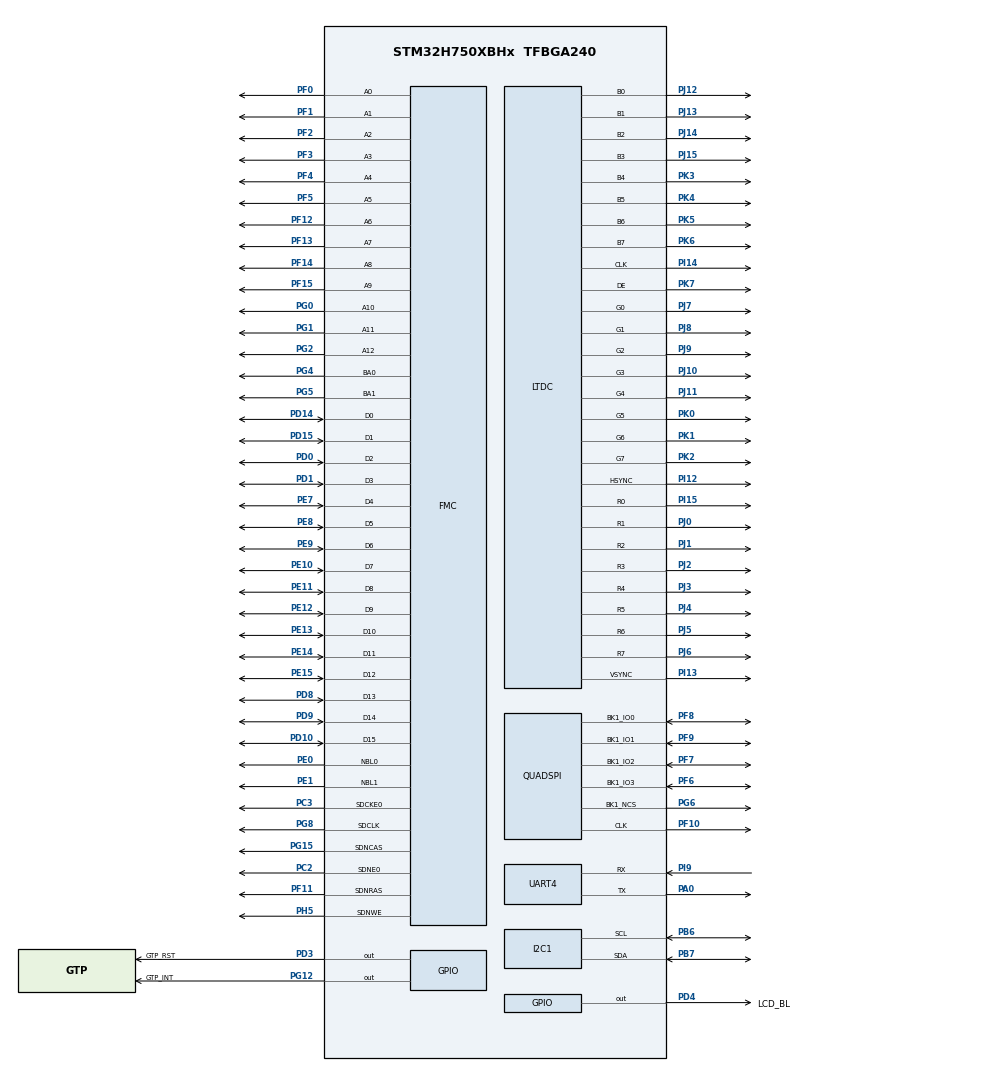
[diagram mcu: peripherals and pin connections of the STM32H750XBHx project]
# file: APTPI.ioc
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CORTEX_M7.BaseAddress-Cortex_Memory_Protection_Unit_Region0_Settings=0xC0000000
CORTEX_M7.CPU_DCache=Enabled
CORTEX_M7.CPU_ICache=Enabled
CORTEX_M7.Enable-Cortex_Memory_Protection_Unit_Region0_Settings=MPU_REGION_ENABLE
CORTEX_M7.IsCacheable-Cortex_Memory_Protection_Unit_Region0_Settings=MPU_ACCESS_CACHEABLE
CORTEX_M7.IsShareable-Cortex_Memory_Protection_Unit_Region0_Settings=MPU_ACCESS_SHAREABLE
CORTEX_M7.MPU_Control=__NULL
CORTEX_M7.Size-Cortex_Memory_Protection_Unit_Region0_Settings=MPU_REGION_SIZE_16MB
DMA2D.ColorMode=DMA2D_OUTPUT_ARGB8888
FMC.BankMapConfig=FMC_SWAPBMAP_DISABLE
FMC.CASLatency1=FMC_SDRAM_CAS_LATENCY_3
FMC.ColumnBitsNumber1=FMC_SDRAM_COLUMN_BITS_NUM_9
FMC.ExitSelfRefreshDelay1=8
FMC.LoadToActiveDelay1=2
FMC.RCDDelay1=2
FMC.RPDelay1=2
FMC.ReadBurst1=FMC_SDRAM_RBURST_ENABLE
FMC.ReadBurst2=FMC_SDRAM_RBURST_ENABLE
FMC.ReadPipeDelay1=FMC_SDRAM_RPIPE_DELAY_1
FMC.ReadPipeDelay2=FMC_SDRAM_RPIPE_DELAY_1
FMC.RowCycleDelay1=7
FMC.RowCycleDelay2=7
FMC.SDClockPeriod1=FMC_SDRAM_CLOCK_PERIOD_2
FMC.SDClockPeriod2=FMC_SDRAM_CLOCK_PERIOD_2
FMC.SelfRefreshTime1=6
FMC.WriteProtection1=FMC_SDRAM_WRITE_PROTECTION_DISABLE
FMC.WriteRecoveryTime1=5
FREERTOS.Tasks01=defaultTask,24,4096,StartDefaultTask,Default,NULL,Dynamic,NULL,NULL
FREERTOS.configTOTAL_HEAP_SIZE=40960
FREERTOS.configUSE_NEWLIB_REENTRANT=1
I2C1.CustomTiming=Enabled
I2C1.I2C_Fall_Time=0
I2C1.I2C_Rise_Time=0
I2C1.Speed=50
I2C1.Timing=0x90913232
LTDC.ActiveW=800
LTDC.Alpha0_L0=0
LTDC.Alpha_L0=0xFF
LTDC.BlendingFactor1_L0=LTDC_BLENDING_FACTOR1_CA
LTDC.BlendingFactor2_L0=LTDC_BLENDING_FACTOR2_CA
LTDC.FBStartAdress_L0=0xC0000000
LTDC.HBP=88
LTDC.HFP=40
LTDC.HSync=1
LTDC.ImageHeight_L0=480
LTDC.ImageWidth_L0=800
LTDC.Layers=0
LTDC.PixelFormat_L0=LTDC_PIXEL_FORMAT_ARGB8888
LTDC.VBP=32
LTDC.VFP=13
LTDC.VSync=1
LTDC.WindowX1_L0=800
LTDC.WindowY1_L0=480
Mcu.Family=STM32H7
Mcu.Name=STM32H750XBHx
Mcu.Package=TFBGA240
NVIC.DMA2D_IRQn=true\:5\:0\:true\:false\:true\:true\:true\:true
NVIC.LTDC_IRQn=true\:5\:0\:true\:false\:true\:true\:true\:true
NVIC.PriorityGroup=NVIC_PRIORITYGROUP_4
NVIC.TIM1_UP_IRQn=true\:15\:0\:false\:false\:true\:false\:false\:true
NVIC.TimeBase=TIM1_UP_IRQn
NVIC.TimeBaseIP=TIM1
PA0.Mode=Asynchronous
PA0.Signal=UART4_TX
PA13\ (JTMS/SWDIO).Mode=Serial_Wire
PA13\ (JTMS/SWDIO).Signal=DEBUG_JTMS-SWDIO
PA14\ (JTCK/SWCLK).Mode=Serial_Wire
PA14\ (JTCK/SWCLK).Signal=DEBUG_JTCK-SWCLK
PA4.GPIO_Speed=GPIO_SPEED_FREQ_VERY_HIGH
PA4.Signal=SPI1_NSS
PA5.GPIO_Speed=GPIO_SPEED_FREQ_VERY_HIGH
PA5.Signal=SPI1_SCK
PB5.GPIO_Speed=GPIO_SPEED_FREQ_VERY_HIGH
PB5.Signal=SPI1_MOSI
PB6.GPIO_Speed=GPIO_SPEED_FREQ_VERY_HIGH
PB6.Mode=I2C
PB6.Signal=I2C1_SCL
PB7.GPIO_Speed=GPIO_SPEED_FREQ_VERY_HIGH
PB7.Mode=I2C
PB7.Signal=I2C1_SDA
PC14-OSC32_IN\ (OSC32_IN).Mode=LSE-External-Oscillator
PC14-OSC32_IN\ (OSC32_IN).Signal=RCC_OSC32_IN
PC15-OSC32_OUT\ (OSC32_OUT).Mode=LSE-External-Oscillator
PC15-OSC32_OUT\ (OSC32_OUT).Signal=RCC_OSC32_OUT
PC2.Mode=SdramChipSelect1_1
PC2.Signal=FMC_SDNE0
PC3.Mode=SdramChipSelect1_1
PC3.Signal=FMC_SDCKE0
PD0.Signal=FMC_D2_DA2
PD1.Signal=FMC_D3_DA3
PD10.Signal=FMC_D15_DA15
PD14.Signal=FMC_D0_DA0
PD15.Signal=FMC_D1_DA1
PD3.GPIO_Label=GTP_RST
PD3.GPIO_PuPd=GPIO_PULLDOWN
PD3.Signal=GPIO_Output
PD4.GPIO_Label=LCD_BL
PD4.PinState=GPIO_PIN_SET
PD4.Signal=GPIO_Output
PD8.Signal=FMC_D13_DA13
PD9.Signal=FMC_D14_DA14
PE0.Signal=FMC_NBL0
PE1.Signal=FMC_NBL1
PE10.Signal=FMC_D7_DA7
PE11.Signal=FMC_D8_DA8
PE12.Signal=FMC_D9_DA9
PE13.Signal=FMC_D10_DA10
PE14.Signal=FMC_D11_DA11
PE15.Signal=FMC_D12_DA12
PE7.Signal=FMC_D4_DA4
PE8.Signal=FMC_D5_DA5
PE9.Signal=FMC_D6_DA6
PF0.Signal=FMC_A0
PF1.Signal=FMC_A1
PF10.GPIO_Speed=GPIO_SPEED_FREQ_VERY_HIGH
PF10.Mode=Single Bank 1
PF10.Signal=QUADSPI_CLK
PF11.Signal=FMC_SDNRAS
PF12.Signal=FMC_A6
PF13.Signal=FMC_A7
PF14.Signal=FMC_A8
PF15.Signal=FMC_A9
PF2.Signal=FMC_A2
PF3.Signal=FMC_A3
PF4.Signal=FMC_A4
PF5.Signal=FMC_A5
PF6.GPIO_Speed=GPIO_SPEED_FREQ_VERY_HIGH
PF6.Mode=Single Bank 1
PF6.Signal=QUADSPI_BK1_IO3
PF7.GPIO_Speed=GPIO_SPEED_FREQ_VERY_HIGH
PF7.Mode=Single Bank 1
PF7.Signal=QUADSPI_BK1_IO2
PF8.GPIO_Speed=GPIO_SPEED_FREQ_VERY_HIGH
PF8.Mode=Single Bank 1
PF8.Signal=QUADSPI_BK1_IO0
PF9.GPIO_Speed=GPIO_SPEED_FREQ_VERY_HIGH
PF9.Mode=Single Bank 1
PF9.Signal=QUADSPI_BK1_IO1
PG0.Signal=FMC_A10
PG1.Signal=FMC_A11
PG12.GPIO_Label=GTP_INT
PG12.GPIO_PuPd=GPIO_PULLDOWN
PG12.Signal=GPIO_Output
PG15.Signal=FMC_SDNCAS
PG2.Signal=FMC_A12
PG4.Signal=FMC_A14_BA0
PG5.Signal=FMC_A15_BA1
PG6.GPIO_Speed=GPIO_SPEED_FREQ_VERY_HIGH
PG6.Mode=Single Bank 1
PG6.Signal=QUADSPI_BK1_NCS
PG8.Signal=FMC_SDCLK
PG9.GPIO_Speed=GPIO_SPEED_FREQ_VERY_HIGH
PG9.Signal=SPI1_MISO
PH0-OSC_IN\ (PH0).Mode=HSE-External-Oscillator
PH0-OSC_IN\ (PH0).Signal=RCC_OSC_IN
PH1-OSC_OUT\ (PH1).Mode=HSE-External-Oscillator
PH1-OSC_OUT\ (PH1).Signal=RCC_OSC_OUT
PH5.Signal=FMC_SDNWE
PI12.Mode=RGB888
PI12.Signal=LTDC_HSYNC
PI13.Mode=RGB888
PI13.Signal=LTDC_VSYNC
PI14.Mode=RGB888
PI14.Signal=LTDC_CLK
PI15.Mode=RGB888
PI15.Signal=LTDC_R0
PI9.Mode=Asynchronous
PI9.Signal=UART4_RX
PJ0.Mode=RGB888
PJ0.Signal=LTDC_R1
PJ1.Mode=RGB888
PJ1.Signal=LTDC_R2
PJ10.Mode=RGB888
PJ10.Signal=LTDC_G3
PJ11.Mode=RGB888
PJ11.Signal=LTDC_G4
PJ12.Mode=RGB888
PJ12.Signal=LTDC_B0
PJ13.Mode=RGB888
PJ13.Signal=LTDC_B1
PJ14.Mode=RGB888
PJ14.Signal=LTDC_B2
PJ15.Mode=RGB888
PJ15.Signal=LTDC_B3
PJ2.Mode=RGB888
PJ2.Signal=LTDC_R3
PJ3.Mode=RGB888
PJ3.Signal=LTDC_R4
PJ4.Mode=RGB888
PJ4.Signal=LTDC_R5
PJ5.Mode=RGB888
PJ5.Signal=LTDC_R6
PJ6.Mode=RGB888
PJ6.Signal=LTDC_R7
PJ7.Mode=RGB888
PJ7.Signal=LTDC_G0
PJ8.Mode=RGB888
PJ8.Signal=LTDC_G1
PJ9.Mode=RGB888
PJ9.Signal=LTDC_G2
PK0.Mode=RGB888
PK0.Signal=LTDC_G5
PK1.Mode=RGB888
PK1.Signal=LTDC_G6
PK2.Mode=RGB888
PK2.Signal=LTDC_G7
PK3.Mode=RGB888
PK3.Signal=LTDC_B4
PK4.Mode=RGB888
PK4.Signal=LTDC_B5
PK5.Mode=RGB888
PK5.Signal=LTDC_B6
PK6.Mode=RGB888
PK6.Signal=LTDC_B7
PK7.Mode=RGB888
PK7.Signal=LTDC_DE
ProjectManager.HeapSize=0x200
ProjectManager.StackSize=0x400
ProjectManager.TargetToolchain=STM32CubeIDE
QUADSPI.ChipSelectHighTime=QSPI_CS_HIGH_TIME_6_CYCLE
QUADSPI.ClockMode=QSPI_CLOCK_MODE_0
QUADSPI.ClockPrescaler=1
QUADSPI.FifoThreshold=4
QUADSPI.FlashSize=22
QUADSPI.SampleShifting=QSPI_SAMPLE_SHIFTING_HALFCYCLE
RCC.ADCFreq_Value=250000000
RCC.APB1Freq_Value=100000000
RCC.APB2Freq_Value=100000000
RCC.APB3Freq_Value=100000000
RCC.APB4Freq_Value=100000000
RCC.CortexFreq_Value=400000000
RCC.D1PPRE=RCC_APB3_DIV2
RCC.D2PPRE1=RCC_APB1_DIV2
RCC.D2PPRE2=RCC_APB2_DIV2
RCC.D3PPRE=RCC_APB4_DIV2
RCC.DIVM1=5
RCC.DIVM2=5
RCC.DIVM3=5
RCC.DIVN1=160
RCC.DIVN2=100
RCC.DIVN3=192
RCC.DIVQ1=8
RCC.DIVR3=32
RCC.FMCCLockSelection=RCC_FMCCLKSOURCE_PLL2
RCC.HCLKFreq_Value=200000000
RCC.HPRE=RCC_HCLK_DIV2
RCC.PLLFRACN=0
RCC.PLLSourceVirtual=RCC_PLLSOURCE_HSE
RCC.PWR_Regulator_Voltage_Scale=PWR_REGULATOR_VOLTAGE_SCALE1
RCC.SYSCLKFreq_VALUE=400000000
RCC.SYSCLKSource=RCC_SYSCLKSOURCE_PLLCLK
RCC.USBFreq_Value=100000000
SH.FMC_A0.0=FMC_A0,13b-sda1
SH.FMC_A1.0=FMC_A1,13b-sda1
SH.FMC_A10.0=FMC_A10,13b-sda1
SH.FMC_A11.0=FMC_A11,13b-sda1
SH.FMC_A12.0=FMC_A12,13b-sda1
SH.FMC_A14_BA0.0=FMC_BA0,FourSdramBanks1
SH.FMC_A15_BA1.0=FMC_BA1,FourSdramBanks1
SH.FMC_A2.0=FMC_A2,13b-sda1
SH.FMC_A3.0=FMC_A3,13b-sda1
SH.FMC_A4.0=FMC_A4,13b-sda1
SH.FMC_A5.0=FMC_A5,13b-sda1
SH.FMC_A6.0=FMC_A6,13b-sda1
SH.FMC_A7.0=FMC_A7,13b-sda1
SH.FMC_A8.0=FMC_A8,13b-sda1
SH.FMC_A9.0=FMC_A9,13b-sda1
SH.FMC_D0_DA0.0=FMC_D0,sd-16b-d1
SH.FMC_D10_DA10.0=FMC_D10,sd-16b-d1
SH.FMC_D11_DA11.0=FMC_D11,sd-16b-d1
SH.FMC_D12_DA12.0=FMC_D12,sd-16b-d1
SH.FMC_D13_DA13.0=FMC_D13,sd-16b-d1
SH.FMC_D14_DA14.0=FMC_D14,sd-16b-d1
SH.FMC_D15_DA15.0=FMC_D15,sd-16b-d1
SH.FMC_D1_DA1.0=FMC_D1,sd-16b-d1
SH.FMC_D2_DA2.0=FMC_D2,sd-16b-d1
SH.FMC_D3_DA3.0=FMC_D3,sd-16b-d1
SH.FMC_D4_DA4.0=FMC_D4,sd-16b-d1
SH.FMC_D5_DA5.0=FMC_D5,sd-16b-d1
SH.FMC_D6_DA6.0=FMC_D6,sd-16b-d1
SH.FMC_D7_DA7.0=FMC_D7,sd-16b-d1
SH.FMC_D8_DA8.0=FMC_D8,sd-16b-d1
SH.FMC_D9_DA9.0=FMC_D9,sd-16b-d1
SH.FMC_NBL0.0=FMC_NBL0,Sd2ByteEnable1
SH.FMC_NBL1.0=FMC_NBL1,Sd2ByteEnable1
SH.FMC_SDCLK.0=FMC_SDCLK,13b-sda1
SH.FMC_SDNCAS.0=FMC_SDNCAS,13b-sda1
SH.FMC_SDNRAS.0=FMC_SDNRAS,13b-sda1
SH.FMC_SDNWE.0=FMC_SDNWE,13b-sda1
STMicroelectronics.X-CUBE-TOUCHGFX.4.18.1.ApplicationCcGraphicsJjApplication=TouchGFXOoGenerator
STMicroelectronics.X-CUBE-TOUCHGFX.4.18.1.tgfx_address1=0xC0000000
STMicroelectronics.X-CUBE-TOUCHGFX.4.18.1.tgfx_address2=0xC1000000
STMicroelectronics.X-CUBE-TOUCHGFX.4.18.1.tgfx_buffering_strategy=Double
STMicroelectronics.X-CUBE-TOUCHGFX.4.18.1.tgfx_display_interface=disp_ltdc
STMicroelectronics.X-CUBE-TOUCHGFX.4.18.1.tgfx_hardware_accelerator=dma_2d
STMicroelectronics.X-CUBE-TOUCHGFX.4.18.1.tgfx_location=By Address
STMicroelectronics.X-CUBE-TOUCHGFX.4.18.1.tgfx_oswrapper=CMSIS V2
STMicroelectronics.X-CUBE-TOUCHGFX.4.18.1.tgfx_pixel_format=ARGB8888\:32
STMicroelectronics.X-CUBE-TOUCHGFX.4.18.1.tgfx_vsync=vsync_ltdc
STMicroelectronics.X-CUBE-TOUCHGFX.4.18.1_IsPackSelfContextualization=true
VP_CRC_VS_CRC.Mode=CRC_Activate
VP_DMA2D_VS_DMA2D.Mode=DMA2D_Activate
VP_FREERTOS_VS_CMSIS_V2.Mode=CMSIS_V2
VP_STMicroelectronics.X-CUBE-TOUCHGFX_VS_GraphicsJjApplication_4.18.1.Mode=GraphicsJjApplication
VP_SYS_VS_tim1.Mode=TIM1
board=custom

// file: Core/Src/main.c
/* USER CODE BEGIN Header */
/**
  ******************************************************************************
  * @file           : main.c
  * @brief          : Main program body
  ******************************************************************************
  * @attention
  *
  * <h2><center>&copy; Copyright (c) 2021 STMicroelectronics.
  * All rights reserved.</center></h2>
  *
  * This software component is licensed by ST under BSD 3-Clause license,
  * the "License"; You may not use this file except in compliance with the
  * License. You may obtain a copy of the License at:
  *                        opensource.org/licenses/BSD-3-Clause
  *
  ******************************************************************************
  */
/* USER CODE END Header */
#include "main.h"
#include "cmsis_os.h"
#include "app_touchgfx.h"

/* USER CODE BEGIN Includes */
#include <stdio.h>
/* USER CODE END Includes */

/* USER CODE BEGIN PD */

  #define REFRESH_COUNT        1953
  #define SDRAM_TIMEOUT                            ((uint32_t)0xFFFF)
  #define SDRAM_MODEREG_BURST_LENGTH_1             ((uint16_t)0x0000)
  #define SDRAM_MODEREG_BURST_LENGTH_2             ((uint16_t)0x0001)
  #define SDRAM_MODEREG_BURST_LENGTH_4             ((uint16_t)0x0002)
  #define SDRAM_MODEREG_BURST_LENGTH_8             ((uint16_t)0x0004)
  #define SDRAM_MODEREG_BURST_TYPE_SEQUENTIAL      ((uint16_t)0x0000)
  #define SDRAM_MODEREG_BURST_TYPE_INTERLEAVED     ((uint16_t)0x0008)
  #define SDRAM_MODEREG_CAS_LATENCY_2              ((uint16_t)0x0020)
  #define SDRAM_MODEREG_CAS_LATENCY_3              ((uint16_t)0x0030)
  #define SDRAM_MODEREG_OPERATING_MODE_STANDARD    ((uint16_t)0x0000)
  #define SDRAM_MODEREG_WRITEBURST_MODE_PROGRAMMED ((uint16_t)0x0000)
  #define SDRAM_MODEREG_WRITEBURST_MODE_SINGLE     ((uint16_t)0x0200)

//  #define GTP_ADDRESS_WRITE          0xBA
//  #define GTP_ADDRESS_READ           0xBB
  #define GTP_ADDRESS_WRITE          0x28
  #define GTP_ADDRESS_READ           0x29
  #define GTP_REG_VERSION       0x8140

  #define QUAD_INOUT_FAST_READ_CMD             0xEB
/* USER CODE END PD */

CRC_HandleTypeDef hcrc;

DMA2D_HandleTypeDef hdma2d;

I2C_HandleTypeDef hi2c1;

LTDC_HandleTypeDef hltdc;

QSPI_HandleTypeDef hqspi;

UART_HandleTypeDef huart4;

SDRAM_HandleTypeDef hsdram1;

/* Definitions for defaultTask */
osThreadId_t defaultTaskHandle;
const osThreadAttr_t defaultTask_attributes = {
  .name = "defaultTask",
  .stack_size = 4096 * 4,
  .priority = (osPriority_t) osPriorityNormal,
};

void SystemClock_Config(void);
static void MX_GPIO_Init(void);
static void MX_UART4_Init(void);
static void MX_QUADSPI_Init(void);
static void MX_FMC_Init(void);
static void MX_CRC_Init(void);
static void MX_DMA2D_Init(void);
static void MX_LTDC_Init(void);
static void MX_I2C1_Init(void);
void StartDefaultTask(void *argument);

/* USER CODE BEGIN PFP */
void MX_SDRAM_InitEx(void);
void QSPI_EnableMemoryMappedMode(void);
void I2C_ResetChip(void);
/* USER CODE END PFP */

/* USER CODE BEGIN 0 */
#ifdef __GNUC__
/* With GCC, small printf (option LD Linker->Libraries->Small printf
   set to 'Yes') calls __io_putchar() */
#define PUTCHAR_PROTOTYPE int __io_putchar(int ch)
#else
#define PUTCHAR_PROTOTYPE int fputc(int ch, FILE *f)
#endif /* __GNUC__ */
PUTCHAR_PROTOTYPE
{
  /* Place your implementation of fputc here */
  /* e.g. write a character to the USART2 and Loop until the end of transmission */
  HAL_UART_Transmit(&huart4, (uint8_t *)&ch, 1, 0xFFFF);
  return ch;
}

/* USER CODE END 0 */

int main(void)
{

  /* Enable I-Cache---------------------------------------------------------*/
  SCB_EnableICache();

  /* Enable D-Cache---------------------------------------------------------*/
  SCB_EnableDCache();

  /* MCU Configuration--------------------------------------------------------*/

  /* Reset of all peripherals, Initializes the Flash interface and the Systick. */
  HAL_Init();

  /* Configure the system clock */
  SystemClock_Config();

  /* Initialize all configured peripherals */
  MX_GPIO_Init();
  MX_UART4_Init();
  MX_QUADSPI_Init();
  MX_FMC_Init();
  MX_CRC_Init();
  MX_DMA2D_Init();
  MX_LTDC_Init();
  MX_I2C1_Init();
  MX_TouchGFX_Init();

  /* Init scheduler */
  osKernelInitialize();

  /* Create the thread(s) */
  /* creation of defaultTask */
  defaultTaskHandle = osThreadNew(StartDefaultTask, NULL, &defaultTask_attributes);

  /* Start scheduler */
  osKernelStart();

  /* We should never get here as control is now taken by the scheduler */
  /* Infinite loop */
  while (1)
  {

  }
}

void SystemClock_Config(void)
{
  RCC_OscInitTypeDef RCC_OscInitStruct = {0};
  RCC_ClkInitTypeDef RCC_ClkInitStruct = {0};

  /** Supply configuration update enable
  */
  HAL_PWREx_ConfigSupply(PWR_LDO_SUPPLY);
  /** Configure the main internal regulator output voltage
  */
  __HAL_PWR_VOLTAGESCALING_CONFIG(PWR_REGULATOR_VOLTAGE_SCALE1);

  while(!__HAL_PWR_GET_FLAG(PWR_FLAG_VOSRDY)) {}
  /** Macro to configure the PLL clock source
  */
  __HAL_RCC_PLL_PLLSOURCE_CONFIG(RCC_PLLSOURCE_HSE);
  /** Initializes the RCC Oscillators according to the specified parameters
  * in the RCC_OscInitTypeDef structure.
  */
  RCC_OscInitStruct.OscillatorType = RCC_OSCILLATORTYPE_HSE;
  RCC_OscInitStruct.HSEState = RCC_HSE_ON;
  RCC_OscInitStruct.PLL.PLLState = RCC_PLL_ON;
  RCC_OscInitStruct.PLL.PLLSource = RCC_PLLSOURCE_HSE;
  RCC_OscInitStruct.PLL.PLLM = 5;
  RCC_OscInitStruct.PLL.PLLN = 160;
  RCC_OscInitStruct.PLL.PLLP = 2;
  RCC_OscInitStruct.PLL.PLLQ = 8;
  RCC_OscInitStruct.PLL.PLLR = 2;
  RCC_OscInitStruct.PLL.PLLRGE = RCC_PLL1VCIRANGE_2;
  RCC_OscInitStruct.PLL.PLLVCOSEL = RCC_PLL1VCOWIDE;
  RCC_OscInitStruct.PLL.PLLFRACN = 0;
  if (HAL_RCC_OscConfig(&RCC_OscInitStruct) != HAL_OK)
  {
    Error_Handler();
  }
  /** Initializes the CPU, AHB and APB buses clocks
  */
  RCC_ClkInitStruct.ClockType = RCC_CLOCKTYPE_HCLK|RCC_CLOCKTYPE_SYSCLK
                              |RCC_CLOCKTYPE_PCLK1|RCC_CLOCKTYPE_PCLK2
                              |RCC_CLOCKTYPE_D3PCLK1|RCC_CLOCKTYPE_D1PCLK1;
  RCC_ClkInitStruct.SYSCLKSource = RCC_SYSCLKSOURCE_PLLCLK;
  RCC_ClkInitStruct.SYSCLKDivider = RCC_SYSCLK_DIV1;
  RCC_ClkInitStruct.AHBCLKDivider = RCC_HCLK_DIV2;
  RCC_ClkInitStruct.APB3CLKDivider = RCC_APB3_DIV2;
  RCC_ClkInitStruct.APB1CLKDivider = RCC_APB1_DIV2;
  RCC_ClkInitStruct.APB2CLKDivider = RCC_APB2_DIV2;
  RCC_ClkInitStruct.APB4CLKDivider = RCC_APB4_DIV2;

  if (HAL_RCC_ClockConfig(&RCC_ClkInitStruct, FLASH_LATENCY_2) != HAL_OK)
  {
    Error_Handler();
  }
}

static void MX_CRC_Init(void)
{

  hcrc.Instance = CRC;
  hcrc.Init.DefaultPolynomialUse = DEFAULT_POLYNOMIAL_ENABLE;
  hcrc.Init.DefaultInitValueUse = DEFAULT_INIT_VALUE_ENABLE;
  hcrc.Init.InputDataInversionMode = CRC_INPUTDATA_INVERSION_NONE;
  hcrc.Init.OutputDataInversionMode = CRC_OUTPUTDATA_INVERSION_DISABLE;
  hcrc.InputDataFormat = CRC_INPUTDATA_FORMAT_BYTES;
  if (HAL_CRC_Init(&hcrc) != HAL_OK)
  {
    Error_Handler();
  }

}

static void MX_DMA2D_Init(void)
{

  hdma2d.Instance = DMA2D;
  hdma2d.Init.Mode = DMA2D_M2M;
  hdma2d.Init.ColorMode = DMA2D_OUTPUT_ARGB8888;
  hdma2d.Init.OutputOffset = 0;
  hdma2d.LayerCfg[1].InputOffset = 0;
  hdma2d.LayerCfg[1].InputColorMode = DMA2D_INPUT_ARGB8888;
  hdma2d.LayerCfg[1].AlphaMode = DMA2D_NO_MODIF_ALPHA;
  hdma2d.LayerCfg[1].InputAlpha = 0;
  hdma2d.LayerCfg[1].AlphaInverted = DMA2D_REGULAR_ALPHA;
  hdma2d.LayerCfg[1].RedBlueSwap = DMA2D_RB_REGULAR;
  hdma2d.LayerCfg[1].ChromaSubSampling = DMA2D_NO_CSS;
  if (HAL_DMA2D_Init(&hdma2d) != HAL_OK)
  {
    Error_Handler();
  }
  if (HAL_DMA2D_ConfigLayer(&hdma2d, 1) != HAL_OK)
  {
    Error_Handler();
  }

}

static void MX_I2C1_Init(void)
{

  hi2c1.Instance = I2C1;
  hi2c1.Init.Timing = 0x90913232;
  hi2c1.Init.OwnAddress1 = 0;
  hi2c1.Init.AddressingMode = I2C_ADDRESSINGMODE_7BIT;
  hi2c1.Init.DualAddressMode = I2C_DUALADDRESS_DISABLE;
  hi2c1.Init.OwnAddress2 = 0;
  hi2c1.Init.OwnAddress2Masks = I2C_OA2_NOMASK;
  hi2c1.Init.GeneralCallMode = I2C_GENERALCALL_DISABLE;
  hi2c1.Init.NoStretchMode = I2C_NOSTRETCH_DISABLE;
  if (HAL_I2C_Init(&hi2c1) != HAL_OK)
  {
    Error_Handler();
  }
  /** Configure Analogue filter
  */
  if (HAL_I2CEx_ConfigAnalogFilter(&hi2c1, I2C_ANALOGFILTER_ENABLE) != HAL_OK)
  {
    Error_Handler();
  }
  /** Configure Digital filter
  */
  if (HAL_I2CEx_ConfigDigitalFilter(&hi2c1, 0) != HAL_OK)
  {
    Error_Handler();
  }
  /* USER CODE BEGIN I2C1_Init 2 */
  I2C_ResetChip();
  /* USER CODE END I2C1_Init 2 */

}

static void MX_LTDC_Init(void)
{

  LTDC_LayerCfgTypeDef pLayerCfg = {0};

  hltdc.Instance = LTDC;
  hltdc.Init.HSPolarity = LTDC_HSPOLARITY_AL;
  hltdc.Init.VSPolarity = LTDC_VSPOLARITY_AL;
  hltdc.Init.DEPolarity = LTDC_DEPOLARITY_AL;
  hltdc.Init.PCPolarity = LTDC_PCPOLARITY_IPC;
  hltdc.Init.HorizontalSync = 0;
  hltdc.Init.VerticalSync = 0;
  hltdc.Init.AccumulatedHBP = 88;
  hltdc.Init.AccumulatedVBP = 32;
  hltdc.Init.AccumulatedActiveW = 888;
  hltdc.Init.AccumulatedActiveH = 512;
  hltdc.Init.TotalWidth = 928;
  hltdc.Init.TotalHeigh = 525;
  hltdc.Init.Backcolor.Blue = 0;
  hltdc.Init.Backcolor.Green = 0;
  hltdc.Init.Backcolor.Red = 0;
  if (HAL_LTDC_Init(&hltdc) != HAL_OK)
  {
    Error_Handler();
  }
  pLayerCfg.WindowX0 = 0;
  pLayerCfg.WindowX1 = 800;
  pLayerCfg.WindowY0 = 0;
  pLayerCfg.WindowY1 = 480;
  pLayerCfg.PixelFormat = LTDC_PIXEL_FORMAT_ARGB8888;
  pLayerCfg.Alpha = 0xFF;
  pLayerCfg.Alpha0 = 0;
  pLayerCfg.BlendingFactor1 = LTDC_BLENDING_FACTOR1_CA;
  pLayerCfg.BlendingFactor2 = LTDC_BLENDING_FACTOR2_CA;
  pLayerCfg.FBStartAdress = 0xC0000000;
  pLayerCfg.ImageWidth = 800;
  pLayerCfg.ImageHeight = 480;
  pLayerCfg.Backcolor.Blue = 0;
  pLayerCfg.Backcolor.Green = 0;
  pLayerCfg.Backcolor.Red = 0;
  if (HAL_LTDC_ConfigLayer(&hltdc, &pLayerCfg, 0) != HAL_OK)
  {
    Error_Handler();
  }

}

static void MX_QUADSPI_Init(void)
{

  /* QUADSPI parameter configuration*/
  hqspi.Instance = QUADSPI;
  hqspi.Init.ClockPrescaler = 1;
  hqspi.Init.FifoThreshold = 4;
  hqspi.Init.SampleShifting = QSPI_SAMPLE_SHIFTING_HALFCYCLE;
  hqspi.Init.FlashSize = 22;
  hqspi.Init.ChipSelectHighTime = QSPI_CS_HIGH_TIME_6_CYCLE;
  hqspi.Init.ClockMode = QSPI_CLOCK_MODE_0;
  hqspi.Init.FlashID = QSPI_FLASH_ID_1;
  hqspi.Init.DualFlash = QSPI_DUALFLASH_DISABLE;
  if (HAL_QSPI_Init(&hqspi) != HAL_OK)
  {
    Error_Handler();
  }
  /* USER CODE BEGIN QUADSPI_Init 2 */
  QSPI_EnableMemoryMappedMode();
  /* USER CODE END QUADSPI_Init 2 */

}

static void MX_UART4_Init(void)
{

  huart4.Instance = UART4;
  huart4.Init.BaudRate = 115200;
  huart4.Init.WordLength = UART_WORDLENGTH_8B;
  huart4.Init.StopBits = UART_STOPBITS_1;
  huart4.Init.Parity = UART_PARITY_NONE;
  huart4.Init.Mode = UART_MODE_TX_RX;
  huart4.Init.HwFlowCtl = UART_HWCONTROL_NONE;
  huart4.Init.OverSampling = UART_OVERSAMPLING_16;
  huart4.Init.OneBitSampling = UART_ONE_BIT_SAMPLE_DISABLE;
  huart4.Init.ClockPrescaler = UART_PRESCALER_DIV1;
  huart4.AdvancedInit.AdvFeatureInit = UART_ADVFEATURE_NO_INIT;
  if (HAL_UART_Init(&huart4) != HAL_OK)
  {
    Error_Handler();
  }
  if (HAL_UARTEx_SetTxFifoThreshold(&huart4, UART_TXFIFO_THRESHOLD_1_8) != HAL_OK)
  {
    Error_Handler();
  }
  if (HAL_UARTEx_SetRxFifoThreshold(&huart4, UART_RXFIFO_THRESHOLD_1_8) != HAL_OK)
  {
    Error_Handler();
  }
  if (HAL_UARTEx_DisableFifoMode(&huart4) != HAL_OK)
  {
    Error_Handler();
  }

}

/* FMC initialization function */
static void MX_FMC_Init(void)
{

  FMC_SDRAM_TimingTypeDef SdramTiming = {0};

  /** Perform the SDRAM1 memory initialization sequence
  */
  hsdram1.Instance = FMC_SDRAM_DEVICE;
  /* hsdram1.Init */
  hsdram1.Init.SDBank = FMC_SDRAM_BANK1;
  hsdram1.Init.ColumnBitsNumber = FMC_SDRAM_COLUMN_BITS_NUM_9;
  hsdram1.Init.RowBitsNumber = FMC_SDRAM_ROW_BITS_NUM_13;
  hsdram1.Init.MemoryDataWidth = FMC_SDRAM_MEM_BUS_WIDTH_16;
  hsdram1.Init.InternalBankNumber = FMC_SDRAM_INTERN_BANKS_NUM_4;
  hsdram1.Init.CASLatency = FMC_SDRAM_CAS_LATENCY_3;
  hsdram1.Init.WriteProtection = FMC_SDRAM_WRITE_PROTECTION_DISABLE;
  hsdram1.Init.SDClockPeriod = FMC_SDRAM_CLOCK_PERIOD_2;
  hsdram1.Init.ReadBurst = FMC_SDRAM_RBURST_ENABLE;
  hsdram1.Init.ReadPipeDelay = FMC_SDRAM_RPIPE_DELAY_1;
  /* SdramTiming */
  SdramTiming.LoadToActiveDelay = 2;
  SdramTiming.ExitSelfRefreshDelay = 8;
  SdramTiming.SelfRefreshTime = 6;
  SdramTiming.RowCycleDelay = 7;
  SdramTiming.WriteRecoveryTime = 5;
  SdramTiming.RPDelay = 2;
  SdramTiming.RCDDelay = 2;

  if (HAL_SDRAM_Init(&hsdram1, &SdramTiming) != HAL_OK)
  {
    Error_Handler( );
  }

  /* USER CODE BEGIN FMC_Init 2 */
  MX_SDRAM_InitEx();
  /* USER CODE END FMC_Init 2 */
}

static void MX_GPIO_Init(void)
{
  GPIO_InitTypeDef GPIO_InitStruct = {0};

  /* GPIO Ports Clock Enable */
  __HAL_RCC_GPIOB_CLK_ENABLE();
  __HAL_RCC_GPIOK_CLK_ENABLE();
  __HAL_RCC_GPIOG_CLK_ENABLE();
  __HAL_RCC_GPIOD_CLK_ENABLE();
  __HAL_RCC_GPIOE_CLK_ENABLE();
  __HAL_RCC_GPIOJ_CLK_ENABLE();
  __HAL_RCC_GPIOA_CLK_ENABLE();
  __HAL_RCC_GPIOC_CLK_ENABLE();
  __HAL_RCC_GPIOI_CLK_ENABLE();
  __HAL_RCC_GPIOF_CLK_ENABLE();
  __HAL_RCC_GPIOH_CLK_ENABLE();

  /*Configure GPIO pin Output Level */
  HAL_GPIO_WritePin(LCD_BL_GPIO_Port, LCD_BL_Pin, GPIO_PIN_SET);

  /*Configure GPIO pin Output Level */
  HAL_GPIO_WritePin(GTP_RST_GPIO_Port, GTP_RST_Pin, GPIO_PIN_RESET);

  /*Configure GPIO pin Output Level */
  HAL_GPIO_WritePin(GTP_INT_GPIO_Port, GTP_INT_Pin, GPIO_PIN_RESET);

  /*Configure GPIO pin : PB5 */
  GPIO_InitStruct.Pin = GPIO_PIN_5;
  GPIO_InitStruct.Mode = GPIO_MODE_AF_PP;
  GPIO_InitStruct.Pull = GPIO_NOPULL;
  GPIO_InitStruct.Speed = GPIO_SPEED_FREQ_VERY_HIGH;
  GPIO_InitStruct.Alternate = GPIO_AF5_SPI1;
  HAL_GPIO_Init(GPIOB, &GPIO_InitStruct);

  /*Configure GPIO pin : PG9 */
  GPIO_InitStruct.Pin = GPIO_PIN_9;
  GPIO_InitStruct.Mode = GPIO_MODE_AF_PP;
  GPIO_InitStruct.Pull = GPIO_NOPULL;
  GPIO_InitStruct.Speed = GPIO_SPEED_FREQ_VERY_HIGH;
  GPIO_InitStruct.Alternate = GPIO_AF5_SPI1;
  HAL_GPIO_Init(GPIOG, &GPIO_InitStruct);

  /*Configure GPIO pin : LCD_BL_Pin */
  GPIO_InitStruct.Pin = LCD_BL_Pin;
  GPIO_InitStruct.Mode = GPIO_MODE_OUTPUT_PP;
  GPIO_InitStruct.Pull = GPIO_NOPULL;
  GPIO_InitStruct.Speed = GPIO_SPEED_FREQ_LOW;
  HAL_GPIO_Init(LCD_BL_GPIO_Port, &GPIO_InitStruct);

  /*Configure GPIO pin : GTP_RST_Pin */
  GPIO_InitStruct.Pin = GTP_RST_Pin;
  GPIO_InitStruct.Mode = GPIO_MODE_OUTPUT_PP;
  GPIO_InitStruct.Pull = GPIO_PULLDOWN;
  GPIO_InitStruct.Speed = GPIO_SPEED_FREQ_LOW;
  HAL_GPIO_Init(GTP_RST_GPIO_Port, &GPIO_InitStruct);

  /*Configure GPIO pin : GTP_INT_Pin */
  GPIO_InitStruct.Pin = GTP_INT_Pin;
  GPIO_InitStruct.Mode = GPIO_MODE_OUTPUT_PP;
  GPIO_InitStruct.Pull = GPIO_PULLDOWN;
  GPIO_InitStruct.Speed = GPIO_SPEED_FREQ_LOW;
  HAL_GPIO_Init(GTP_INT_GPIO_Port, &GPIO_InitStruct);

  /*Configure GPIO pins : PA5 PA4 */
  GPIO_InitStruct.Pin = GPIO_PIN_5|GPIO_PIN_4;
  GPIO_InitStruct.Mode = GPIO_MODE_AF_PP;
  GPIO_InitStruct.Pull = GPIO_NOPULL;
  GPIO_InitStruct.Speed = GPIO_SPEED_FREQ_VERY_HIGH;
  GPIO_InitStruct.Alternate = GPIO_AF5_SPI1;
  HAL_GPIO_Init(GPIOA, &GPIO_InitStruct);

}

/* USER CODE BEGIN 4 */

void MX_SDRAM_InitEx(void)
  {
    __IO uint32_t tmpmrd = 0;
    FMC_SDRAM_CommandTypeDef Command;
    /* Step 1: Configure a clock configuration enable command */
    Command.CommandMode            = FMC_SDRAM_CMD_CLK_ENABLE;
    Command.CommandTarget          =  FMC_SDRAM_CMD_TARGET_BANK1;
    Command.AutoRefreshNumber      = 1;
    Command.ModeRegisterDefinition = 0;

    /* Send the command */
    HAL_SDRAM_SendCommand(&hsdram1, &Command, SDRAM_TIMEOUT);

    /* Step 2: Insert 100 us minimum delay */
    /* Inserted delay is equal to 1 ms due to systick time base unit (ms) */
    HAL_Delay(1);

    /* Step 3: Configure a PALL (precharge all) command */
    Command.CommandMode            = FMC_SDRAM_CMD_PALL;
    Command.CommandTarget          = FMC_SDRAM_CMD_TARGET_BANK1;
    Command.AutoRefreshNumber      = 1;
    Command.ModeRegisterDefinition = 0;

    /* Send the command */
    HAL_SDRAM_SendCommand(&hsdram1, &Command, SDRAM_TIMEOUT);

    /* Step 4: Configure an Auto Refresh command */
    Command.CommandMode            = FMC_SDRAM_CMD_AUTOREFRESH_MODE;
    Command.CommandTarget          = FMC_SDRAM_CMD_TARGET_BANK1;
    Command.AutoRefreshNumber      = 8;
    Command.ModeRegisterDefinition = 0;

    /* Send the command */
    HAL_SDRAM_SendCommand(&hsdram1, &Command, SDRAM_TIMEOUT);

    /* Step 5: Program the external memory mode register */
    tmpmrd = (uint32_t)SDRAM_MODEREG_BURST_LENGTH_1          |\
                       SDRAM_MODEREG_BURST_TYPE_SEQUENTIAL   |\
                       SDRAM_MODEREG_CAS_LATENCY_3           |\
                       SDRAM_MODEREG_OPERATING_MODE_STANDARD |\
                       SDRAM_MODEREG_WRITEBURST_MODE_SINGLE;

    Command.CommandMode            = FMC_SDRAM_CMD_LOAD_MODE;
    Command.CommandTarget          = FMC_SDRAM_CMD_TARGET_BANK1;
    Command.AutoRefreshNumber      = 1;
    Command.ModeRegisterDefinition = tmpmrd;

    /* Send the command */
    HAL_SDRAM_SendCommand(&hsdram1, &Command, SDRAM_TIMEOUT);

    /* Step 6: Set the refresh rate counter */
    /* Set the device refresh rate */
    HAL_SDRAM_ProgramRefreshRate(&hsdram1, REFRESH_COUNT);
  }
void QSPI_EnableMemoryMappedMode(void)
{
  QSPI_CommandTypeDef      s_command;
  QSPI_MemoryMappedTypeDef s_mem_mapped_cfg;

  /* Configure the command for the read instruction */
  s_command.InstructionMode   = QSPI_INSTRUCTION_1_LINE;
  s_command.Instruction       = QUAD_INOUT_FAST_READ_CMD;
  s_command.AddressMode       = QSPI_ADDRESS_4_LINES;
  s_command.AddressSize       = QSPI_ADDRESS_24_BITS;
  s_command.AlternateByteMode = QSPI_ALTERNATE_BYTES_NONE;
  s_command.DataMode          = QSPI_DATA_4_LINES;
  s_command.DummyCycles       = 6;
  s_command.DdrMode           = QSPI_DDR_MODE_DISABLE;
  s_command.DdrHoldHalfCycle  = QSPI_DDR_HHC_HALF_CLK_DELAY;
  s_command.SIOOMode          = QSPI_SIOO_INST_EVERY_CMD;

  /* Configure the memory mapped mode */
  s_mem_mapped_cfg.TimeOutActivation = QSPI_TIMEOUT_COUNTER_DISABLE;
  s_mem_mapped_cfg.TimeOutPeriod     = 0;

  HAL_QSPI_MemoryMapped(&hqspi, &s_command, &s_mem_mapped_cfg);
}

void I2C_ResetChip(void)
{
	GPIO_InitTypeDef GPIO_InitStructure;

	//配置 INT引脚，下拉推挽输
	GPIO_InitStructure.Pin = GTP_INT_Pin;
	GPIO_InitStructure.Mode = GPIO_MODE_OUTPUT_PP;
	GPIO_InitStructure.Speed = GPIO_SPEED_FREQ_HIGH;
	GPIO_InitStructure.Pull  = GPIO_PULLUP;       //设置为上
	HAL_GPIO_Init(GTP_INT_GPIO_Port, &GPIO_InitStructure);

	HAL_GPIO_WritePin (GTP_INT_GPIO_Port,GTP_INT_Pin,GPIO_PIN_SET);
	HAL_GPIO_WritePin (GTP_RST_GPIO_Port,GTP_RST_Pin,GPIO_PIN_RESET);
	HAL_Delay(10);
	HAL_GPIO_WritePin (GTP_RST_GPIO_Port,GTP_RST_Pin,GPIO_PIN_SET);
	HAL_Delay(20);

	/*把INT引脚设置为浮空输入模式，以便接收触摸中断信号*/
	GPIO_InitStructure.Pin = GTP_INT_Pin;
	GPIO_InitStructure.Mode = GPIO_MODE_INPUT;
	GPIO_InitStructure.Speed = GPIO_SPEED_FREQ_HIGH;
	GPIO_InitStructure.Pull  = GPIO_NOPULL;
	HAL_GPIO_Init(GTP_INT_GPIO_Port, &GPIO_InitStructure);
	HAL_Delay(100);

//	buf[0]=0x80;
//	buf[1]=0xFF;
//	buf[2]=0;
//	buf[3]=1;
//	HAL_I2C_Master_Transmit(&hi2c1,GTP_ADDRESS_WRITE,&GT9147_CFG_TBL[0],sizeof(GT9147_CFG_TBL),1000);
//	for(int i=2;i<sizeof(GT9147_CFG_TBL);i++)buf[2]+=GT9147_CFG_TBL[i];
//    buf[2]=(~buf[2])+1;
//	HAL_I2C_Master_Transmit(&hi2c1,GTP_ADDRESS_WRITE,&buf[0],2,1000);
}

/* USER CODE END 4 */

void StartDefaultTask(void *argument)
{
  /* USER CODE BEGIN 5 */
  /* Infinite loop */
  for(;;)
  {
	MX_TouchGFX_Process();
	osDelay(1);
  }
  /* USER CODE END 5 */
}

void HAL_TIM_PeriodElapsedCallback(TIM_HandleTypeDef *htim)
{
  if (htim->Instance == TIM1) {
    HAL_IncTick();
  }
}

void Error_Handler(void)
{
  __disable_irq();
  while (1)
  {
  }
}
